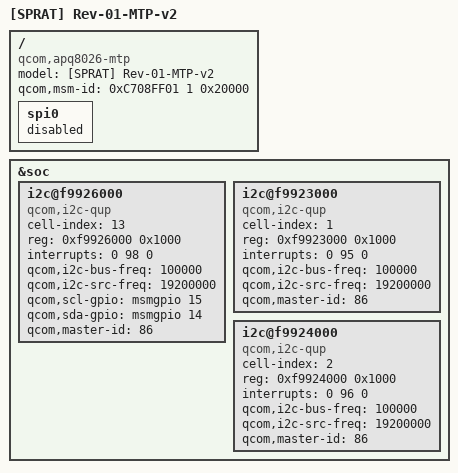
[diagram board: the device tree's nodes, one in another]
/* Copyright (c) 2013, The Linux Foundation. All rights reserved.
 *
 * This program is free software; you can redistribute it and/or modify
 * it under the terms of the GNU General Public License version 2 and
 * only version 2 as published by the Free Software Foundation.
 *
 * This program is distributed in the hope that it will be useful,
 * but WITHOUT ANY WARRANTY; without even the implied warranty of
 * MERCHANTABILITY or FITNESS FOR A PARTICULAR PURPOSE.  See the
 * GNU General Public License for more details.
 */

/* qcom,msm-id =<DT_INFO SS_BOARD_HARDWARE_REV QC_SOC_REVISION>
 * All these three fields are unsigned 32 bit integers
 * DT_INFO = [31:24] chip-id, [23:16] platform-id, [15:8] national code, [7:0] operator revision[ reserved]
 * SS_BOARD_HARDWARE_REV = Samsung specific hardware Revision
 * QC_SOC_REVISION = Qcomm SOC Version of MTP Board
 * Please refer to .../lk/platform/msm_shared/dev_tree.c also
 */

/dts-v1/;
/include/ "apq8026-sprat/apq8026-v2.dtsi"
/include/ "apq8026-sprat/msm8226-sprat-r01.dtsi"

/ {
	model = "[SPRAT] Rev-01-MTP-v2";
	compatible = "qcom,apq8026-mtp", "qcom,apq8026", "qcom,mtp";
	qcom,msm-id = <0xC708FF01 1 0x20000>;
};

/{
        spi0{
        status = "disable";
        };

};

&soc {
	/*Adding node for the MAX77693 I2C QUP Interface*/
        i2c@f9926000 { /* BLSP-1 QUP-3 */
                cell-index = <13>;
                compatible = "qcom,i2c-qup";
                reg = <0xf9926000 0x1000>;
                #address-cells = <1>;
                #size-cells = <0>;
                reg-names = "qup_phys_addr";
                interrupts = <0 98 0>;
                interrupt-names = "qup_err_intr";
                qcom,i2c-bus-freq = <100000>;
                qcom,i2c-src-freq = <19200000>;
                qcom,scl-gpio = <&msmgpio 15 0>;
                qcom,sda-gpio = <&msmgpio 14 0>;
                qcom,master-id = <86>;
	};

	i2c@f9923000 { /* BLSP-1 QUP-1 */
		cell-index = <1>;
		compatible = "qcom,i2c-qup";
		reg = <0xf9923000 0x1000>;
		#address-cells = <1>;
		#size-cells = <0>;
		reg-names = "qup_phys_addr";
		interrupts = <0 95 0>;
		interrupt-names = "qup_err_intr";
		qcom,i2c-bus-freq = <100000>;
		qcom,i2c-src-freq = <19200000>;
                qcom,master-id = <86>;
		status = "okay";
	};

	i2c@f9924000 { /* BLSP-1 QUP-2 */
		cell-index = <2>;
		compatible = "qcom,i2c-qup";
		reg = <0xf9924000 0x1000>;
		#address-cells = <1>;
		#size-cells = <0>;
		reg-names = "qup_phys_addr";
		interrupts = <0 96 0>;
		interrupt-names = "qup_err_intr";
		qcom,i2c-bus-freq = <100000>;
		qcom,i2c-src-freq = <19200000>;
                qcom,master-id = <86>;
	};
};
